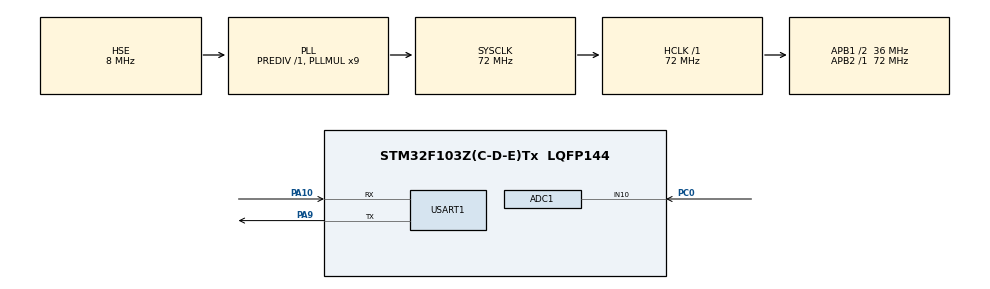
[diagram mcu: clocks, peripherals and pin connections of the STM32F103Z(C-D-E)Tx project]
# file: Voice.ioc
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ADC1.Channel-0\#ChannelRegularConversion=ADC_CHANNEL_10
ADC1.NbrOfConversionFlag=1
ADC1.Rank-0\#ChannelRegularConversion=1
ADC1.SamplingTime-0\#ChannelRegularConversion=ADC_SAMPLETIME_239CYCLES_5
ADC1.master=1
Mcu.Family=STM32F1
Mcu.Name=STM32F103Z(C-D-E)Tx
Mcu.Package=LQFP144
NVIC.ADC1_2_IRQn=true\:0\:0\:false\:false\:true\:true\:true\:true
NVIC.PriorityGroup=NVIC_PRIORITYGROUP_4
NVIC.TIM2_IRQn=true\:0\:0\:false\:false\:true\:true\:true\:true
OSC_IN.Mode=HSE-External-Oscillator
OSC_IN.Signal=RCC_OSC_IN
OSC_OUT.Mode=HSE-External-Oscillator
OSC_OUT.Signal=RCC_OSC_OUT
PA10.Mode=Asynchronous
PA10.Signal=USART1_RX
PA13.Mode=Serial_Wire
PA13.Signal=SYS_JTMS-SWDIO
PA14.Mode=Serial_Wire
PA14.Signal=SYS_JTCK-SWCLK
PA9.Mode=Asynchronous
PA9.Signal=USART1_TX
PC0.Signal=ADCx_IN10
PC14-OSC32_IN.Mode=LSE-External-Oscillator
PC14-OSC32_IN.Signal=RCC_OSC32_IN
PC15-OSC32_OUT.Mode=LSE-External-Oscillator
PC15-OSC32_OUT.Signal=RCC_OSC32_OUT
ProjectManager.HeapSize=0x200
ProjectManager.StackSize=0x400
ProjectManager.TargetToolchain=MDK-ARM V5.32
RCC.ADCPresc=RCC_ADCPCLK2_DIV6
RCC.AHBFreq_Value=72000000
RCC.APB1CLKDivider=RCC_HCLK_DIV2
RCC.APB1Freq_Value=36000000
RCC.APB1TimFreq_Value=72000000
RCC.APB2Freq_Value=72000000
RCC.APB2TimFreq_Value=72000000
RCC.HCLKFreq_Value=72000000
RCC.PLLMUL=RCC_PLL_MUL9
RCC.PLLSourceVirtual=RCC_PLLSOURCE_HSE
RCC.SYSCLKFreq_VALUE=72000000
RCC.SYSCLKSource=RCC_SYSCLKSOURCE_PLLCLK
RCC.USBFreq_Value=72000000
SH.ADCx_IN10.0=ADC1_IN10,IN10
TIM2.Period=10000-1
TIM2.Prescaler=7200-1
USART1.VirtualMode=VM_ASYNC
VP_TIM2_VS_ClockSourceINT.Mode=Internal
board=custom

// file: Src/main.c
/* USER CODE BEGIN Header */
/**
	 ******************************************************************************
	* @file           : main.c
	* @brief          : Main program body
	******************************************************************************
	* @attention
	*
	* Copyright (c) 2024 STMicroelectronics.
	* All rights reserved.
	*
	* This software is licensed under terms that can be found in the LICENSE file
	* in the root directory of this software component.
	* If no LICENSE file comes with this software, it is provided AS-IS.
	*
	******************************************************************************
	*/
/* USER CODE END Header */
#include "main.h"
#include "adc.h"
#include "tim.h"
#include "usart.h"
#include "gpio.h"

/* USER CODE BEGIN Includes */
#include <stdio.h>
#include "voice.h"
/* USER CODE END Includes */

void SystemClock_Config(void);

/* USER CODE BEGIN 0 */
int fputc(int ch, FILE * f)
{
	HAL_UART_Transmit(&huart1,(uint8_t *)&ch,1,1000);
	return ch;
}

void HAL_TIM_PeriodElapsedCallback(TIM_HandleTypeDef *htim)
{
	if(htim->Instance == TIM2)
	{
		voice_get(&battery);

		printf("battery: %.2f\n",battery.adc_v);
	}
}

/* USER CODE END 0 */

int main(void)
{

	/* MCU Configuration--------------------------------------------------------*/

	/* Reset of all peripherals, Initializes the Flash interface and the Systick. */
	HAL_Init();

	/* Configure the system clock */
	SystemClock_Config();

	/* Initialize all configured peripherals */
	MX_GPIO_Init();
	MX_ADC1_Init();
	MX_USART1_UART_Init();
	MX_TIM2_Init();
	/* USER CODE BEGIN 2 */
	voice_init();
	HAL_TIM_Base_Start_IT(&htim2);
	/* USER CODE END 2 */

	/* Infinite loop */
	while (1)
	{

	}
}

void SystemClock_Config(void)
{
	RCC_OscInitTypeDef RCC_OscInitStruct = {0};
	RCC_ClkInitTypeDef RCC_ClkInitStruct = {0};
	RCC_PeriphCLKInitTypeDef PeriphClkInit = {0};

	/** Initializes the RCC Oscillators according to the specified parameters
	 * in the RCC_OscInitTypeDef structure.
	 */
	RCC_OscInitStruct.OscillatorType = RCC_OSCILLATORTYPE_HSE;
	RCC_OscInitStruct.HSEState = RCC_HSE_ON;
	RCC_OscInitStruct.HSEPredivValue = RCC_HSE_PREDIV_DIV1;
	RCC_OscInitStruct.HSIState = RCC_HSI_ON;
	RCC_OscInitStruct.PLL.PLLState = RCC_PLL_ON;
	RCC_OscInitStruct.PLL.PLLSource = RCC_PLLSOURCE_HSE;
	RCC_OscInitStruct.PLL.PLLMUL = RCC_PLL_MUL9;
	if (HAL_RCC_OscConfig(&RCC_OscInitStruct) != HAL_OK)
	{
	Error_Handler();
	}

	/** Initializes the CPU, AHB and APB buses clocks
	 */
	RCC_ClkInitStruct.ClockType = RCC_CLOCKTYPE_HCLK|RCC_CLOCKTYPE_SYSCLK
								|RCC_CLOCKTYPE_PCLK1|RCC_CLOCKTYPE_PCLK2;
	RCC_ClkInitStruct.SYSCLKSource = RCC_SYSCLKSOURCE_PLLCLK;
	RCC_ClkInitStruct.AHBCLKDivider = RCC_SYSCLK_DIV1;
	RCC_ClkInitStruct.APB1CLKDivider = RCC_HCLK_DIV2;
	RCC_ClkInitStruct.APB2CLKDivider = RCC_HCLK_DIV1;

	if (HAL_RCC_ClockConfig(&RCC_ClkInitStruct, FLASH_LATENCY_2) != HAL_OK)
	{
	Error_Handler();
	}
	PeriphClkInit.PeriphClockSelection = RCC_PERIPHCLK_ADC;
	PeriphClkInit.AdcClockSelection = RCC_ADCPCLK2_DIV6;
	if (HAL_RCCEx_PeriphCLKConfig(&PeriphClkInit) != HAL_OK)
	{
	Error_Handler();
	}
}

void Error_Handler(void)
{
	__disable_irq();
	while (1)
	{
	}
}
